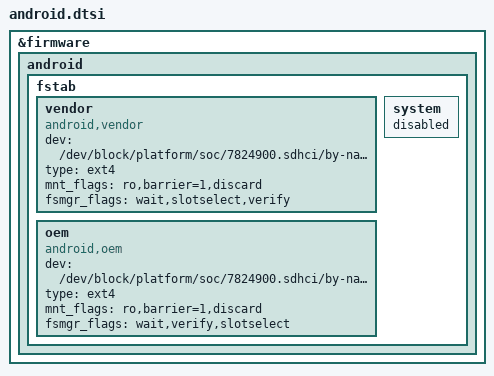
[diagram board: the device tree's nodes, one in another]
/* Copyright (c) 2018, Motorola Mobility Inc. All rights reserved.
 *
 * This program is free software; you can redistribute it and/or modify
 * it under the terms of the GNU General Public License version 2 and
 * only version 2 as published by the Free Software Foundation.
 *
 * This program is distributed in the hope that it will be useful,
 * but WITHOUT ANY WARRANTY; without even the implied warranty of
 * MERCHANTABILITY or FITNESS FOR A PARTICULAR PURPOSE.  See the
 * GNU General Public License for more details.
 */

&firmware {
        android {
                fstab {
                        vendor {
                                compatible = "android,vendor";
                                dev = "/dev/block/platform/soc/7824900.sdhci/by-name/vendor";
                                type = "ext4";
                                mnt_flags = "ro,barrier=1,discard";
                                fsmgr_flags = "wait,slotselect,verify";
                                status = "ok";
                        };
                        oem {
                                compatible = "android,oem";
                                dev = "/dev/block/platform/soc/7824900.sdhci/by-name/oem";
                                type = "ext4";
                                mnt_flags = "ro,barrier=1,discard";
                                fsmgr_flags = "wait,verify,slotselect";
                                status = "ok";
                        };
                        system {
                                status = "disable";
                        };
                };
        };
};
